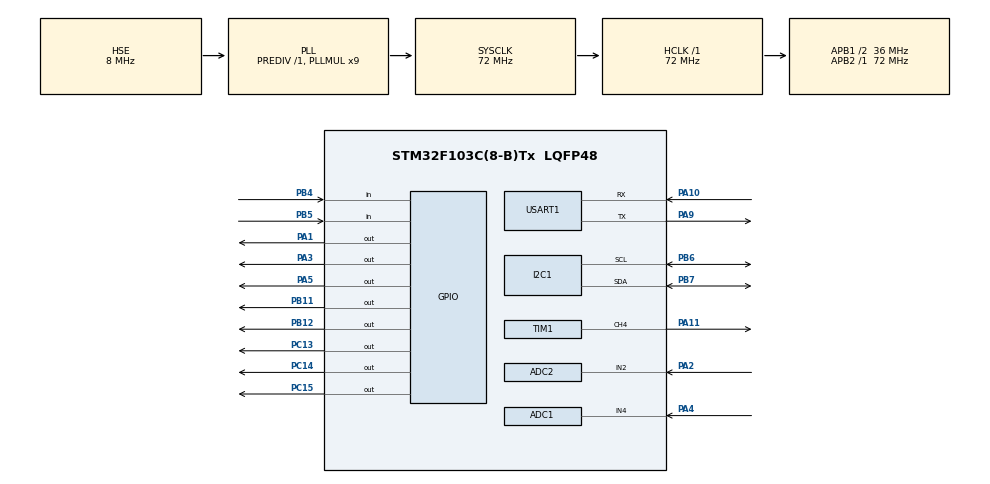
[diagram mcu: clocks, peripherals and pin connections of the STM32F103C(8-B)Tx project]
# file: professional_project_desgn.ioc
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ADC1.Channel-1\#ChannelRegularConversion=ADC_CHANNEL_4
ADC1.ExternalTrigConv=ADC_SOFTWARE_START
ADC1.NbrOfConversionFlag=1
ADC1.Rank-1\#ChannelRegularConversion=1
ADC1.SamplingTime-1\#ChannelRegularConversion=ADC_SAMPLETIME_71CYCLES_5
ADC1.master=1
ADC2.Channel-12\#ChannelRegularConversion=ADC_CHANNEL_2
ADC2.NbrOfConversionFlag=1
ADC2.Rank-12\#ChannelRegularConversion=1
ADC2.SamplingTime-12\#ChannelRegularConversion=ADC_SAMPLETIME_71CYCLES_5
Dma.Request0=USART1_TX
Dma.USART1_TX.0.Direction=DMA_MEMORY_TO_PERIPH
Dma.USART1_TX.0.Instance=DMA1_Channel4
Dma.USART1_TX.0.MemDataAlignment=DMA_MDATAALIGN_BYTE
Dma.USART1_TX.0.MemInc=DMA_MINC_ENABLE
Dma.USART1_TX.0.Mode=DMA_NORMAL
Dma.USART1_TX.0.PeriphDataAlignment=DMA_PDATAALIGN_BYTE
Dma.USART1_TX.0.PeriphInc=DMA_PINC_DISABLE
Dma.USART1_TX.0.Priority=DMA_PRIORITY_LOW
Mcu.Family=STM32F1
Mcu.Name=STM32F103C(8-B)Tx
Mcu.Package=LQFP48
NVIC.ADC1_2_IRQn=true\:1\:0\:true\:false\:true\:true\:true\:true
NVIC.DMA1_Channel4_IRQn=true\:0\:0\:false\:false\:true\:false\:true\:true
NVIC.PriorityGroup=NVIC_PRIORITYGROUP_4
NVIC.TIM1_UP_IRQn=true\:0\:0\:false\:false\:true\:true\:true\:true
NVIC.TIM2_IRQn=true\:0\:0\:true\:false\:true\:true\:true\:true
NVIC.TIM3_IRQn=true\:0\:0\:false\:false\:true\:true\:true\:true
NVIC.TIM4_IRQn=true\:0\:0\:true\:false\:true\:true\:true\:true
NVIC.USART1_IRQn=true\:0\:0\:false\:false\:true\:true\:true\:true
PA1.PinState=GPIO_PIN_SET
PA1.Signal=GPIO_Output
PA10.Mode=Asynchronous
PA10.Signal=USART1_RX
PA11.Signal=S_TIM1_CH4
PA13.Mode=Serial_Wire
PA13.Signal=SYS_JTMS-SWDIO
PA14.Mode=Serial_Wire
PA14.Signal=SYS_JTCK-SWCLK
PA2.Signal=ADCx_IN2
PA3.Signal=GPIO_Output
PA4.Signal=ADCx_IN4
PA5.GPIO_PuPd=GPIO_PULLUP
PA5.PinState=GPIO_PIN_SET
PA5.Signal=GPIO_Output
PA9.Mode=Asynchronous
PA9.Signal=USART1_TX
PB11.GPIO_PuPd=GPIO_PULLUP
PB11.Signal=GPIO_Output
PB12.Signal=GPIO_Output
PB4.Signal=GPIO_Input
PB5.GPIO_PuPd=GPIO_PULLDOWN
PB5.Signal=GPIO_Input
PB6.Mode=I2C
PB6.Signal=I2C1_SCL
PB7.Mode=I2C
PB7.Signal=I2C1_SDA
PC13-TAMPER-RTC.Signal=GPIO_Output
PC14-OSC32_IN.GPIO_PuPd=GPIO_PULLUP
PC14-OSC32_IN.Signal=GPIO_Output
PC15-OSC32_OUT.GPIO_PuPd=GPIO_PULLUP
PC15-OSC32_OUT.Signal=GPIO_Output
PD0-OSC_IN.Mode=HSE-External-Oscillator
PD0-OSC_IN.Signal=RCC_OSC_IN
PD1-OSC_OUT.Mode=HSE-External-Oscillator
PD1-OSC_OUT.Signal=RCC_OSC_OUT
ProjectManager.HeapSize=0x200
ProjectManager.StackSize=0x400
ProjectManager.TargetToolchain=MDK-ARM V5.27
RCC.ADCPresc=RCC_ADCPCLK2_DIV6
RCC.AHBFreq_Value=72000000
RCC.APB1CLKDivider=RCC_HCLK_DIV2
RCC.APB1Freq_Value=36000000
RCC.APB1TimFreq_Value=72000000
RCC.APB2Freq_Value=72000000
RCC.APB2TimFreq_Value=72000000
RCC.HCLKFreq_Value=72000000
RCC.PLLMUL=RCC_PLL_MUL9
RCC.PLLSourceVirtual=RCC_PLLSOURCE_HSE
RCC.SYSCLKFreq_VALUE=72000000
RCC.SYSCLKSource=RCC_SYSCLKSOURCE_PLLCLK
RCC.USBFreq_Value=72000000
SH.ADCx_IN2.0=ADC2_IN2,IN2
SH.ADCx_IN4.0=ADC1_IN4,IN4
SH.ADCx_IN4.1=ADC2_IN4
SH.S_TIM1_CH4.0=TIM1_CH4,PWM Generation4 CH4
TIM1.AutoReloadPreload=TIM_AUTORELOAD_PRELOAD_ENABLE
TIM1.Channel-PWM\ Generation4\ CH4=TIM_CHANNEL_4
TIM1.Period=999
TIM1.Prescaler=719
TIM1.Pulse-PWM\ Generation4\ CH4=499
TIM2.AutoReloadPreload=TIM_AUTORELOAD_PRELOAD_ENABLE
TIM2.Period=999
TIM2.Prescaler=719
TIM3.AutoReloadPreload=TIM_AUTORELOAD_PRELOAD_ENABLE
TIM3.Prescaler=71
TIM4.AutoReloadPreload=TIM_AUTORELOAD_PRELOAD_ENABLE
TIM4.Period=124
TIM4.Prescaler=71
USART1.VirtualMode=VM_ASYNC
VP_TIM1_VS_ClockSourceINT.Mode=Internal
VP_TIM2_VS_ClockSourceINT.Mode=Internal
VP_TIM3_VS_ClockSourceINT.Mode=Internal
VP_TIM4_VS_ClockSourceINT.Mode=Internal
board=custom

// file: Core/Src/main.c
/* USER CODE BEGIN Header */
/**
  ******************************************************************************
  * @file           : main.c
  * @brief          : Main program body
  ******************************************************************************
  * @attention
  *
  * Copyright (c) 2025 STMicroelectronics.
  * All rights reserved.
  *
  * This software is licensed under terms that can be found in the LICENSE file
  * in the root directory of this software component.
  * If no LICENSE file comes with this software, it is provided AS-IS.
  *
  ******************************************************************************
  */
/* USER CODE END Header */
#include "main.h"
#include "adc.h"
#include "dma.h"
#include "i2c.h"
#include "tim.h"
#include "usart.h"
#include "gpio.h"

/* USER CODE BEGIN Includes */
#include "bspsystem.h"
/* USER CODE END Includes */

void SystemClock_Config(void);

int main(void)
{

  /* MCU Configuration--------------------------------------------------------*/

  /* Reset of all peripherals, Initializes the Flash interface and the Systick. */
  HAL_Init();

  /* USER CODE BEGIN Init */
  schedule_init();
  /* USER CODE END Init */

  /* Configure the system clock */
  SystemClock_Config();

  /* Initialize all configured peripherals */
  MX_GPIO_Init();
  MX_DMA_Init();
  MX_I2C1_Init();
  MX_ADC1_Init();
  MX_TIM2_Init();
  MX_ADC2_Init();
  MX_TIM4_Init();
  MX_TIM1_Init();
  MX_TIM3_Init();
  MX_USART1_UART_Init();
  /* USER CODE BEGIN 2 */
	OLED_Init();
	OLED_Clear();
	HAL_TIM_Base_Start_IT(&htim4);
	HAL_TIM_PWM_Start(&htim1,TIM_CHANNEL_4);
	__HAL_TIM_SET_COMPARE(&htim1,TIM_CHANNEL_4,0);
	DHT11_Init();
	HAL_Delay(1000);
  /* USER CODE END 2 */

  /* Infinite loop */
  while (1)
  {

    /* USER CODE BEGIN 3 */

		schedule_pro();

  }
  /* USER CODE END 3 */
}

void SystemClock_Config(void)
{
  RCC_OscInitTypeDef RCC_OscInitStruct = {0};
  RCC_ClkInitTypeDef RCC_ClkInitStruct = {0};
  RCC_PeriphCLKInitTypeDef PeriphClkInit = {0};

  /** Initializes the RCC Oscillators according to the specified parameters
  * in the RCC_OscInitTypeDef structure.
  */
  RCC_OscInitStruct.OscillatorType = RCC_OSCILLATORTYPE_HSE;
  RCC_OscInitStruct.HSEState = RCC_HSE_ON;
  RCC_OscInitStruct.HSEPredivValue = RCC_HSE_PREDIV_DIV1;
  RCC_OscInitStruct.HSIState = RCC_HSI_ON;
  RCC_OscInitStruct.PLL.PLLState = RCC_PLL_ON;
  RCC_OscInitStruct.PLL.PLLSource = RCC_PLLSOURCE_HSE;
  RCC_OscInitStruct.PLL.PLLMUL = RCC_PLL_MUL9;
  if (HAL_RCC_OscConfig(&RCC_OscInitStruct) != HAL_OK)
  {
    Error_Handler();
  }

  /** Initializes the CPU, AHB and APB buses clocks
  */
  RCC_ClkInitStruct.ClockType = RCC_CLOCKTYPE_HCLK|RCC_CLOCKTYPE_SYSCLK
                              |RCC_CLOCKTYPE_PCLK1|RCC_CLOCKTYPE_PCLK2;
  RCC_ClkInitStruct.SYSCLKSource = RCC_SYSCLKSOURCE_PLLCLK;
  RCC_ClkInitStruct.AHBCLKDivider = RCC_SYSCLK_DIV1;
  RCC_ClkInitStruct.APB1CLKDivider = RCC_HCLK_DIV2;
  RCC_ClkInitStruct.APB2CLKDivider = RCC_HCLK_DIV1;

  if (HAL_RCC_ClockConfig(&RCC_ClkInitStruct, FLASH_LATENCY_2) != HAL_OK)
  {
    Error_Handler();
  }
  PeriphClkInit.PeriphClockSelection = RCC_PERIPHCLK_ADC;
  PeriphClkInit.AdcClockSelection = RCC_ADCPCLK2_DIV6;
  if (HAL_RCCEx_PeriphCLKConfig(&PeriphClkInit) != HAL_OK)
  {
    Error_Handler();
  }
}

void Error_Handler(void)
{
  __disable_irq();
  while (1)
  {
  }
}
